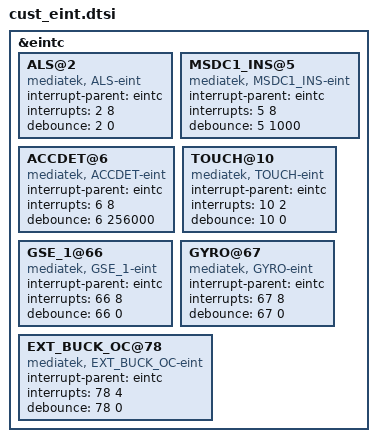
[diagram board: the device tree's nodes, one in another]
/*
 * Generated by MTK SP DrvGen Version 03.13.6 for MT6735M. Copyright MediaTek Inc. (C) 2013.
 * Fri Jan 06 15:19:48 2017
 * Do Not Modify the File.
 */

/*************************
 * EINT DTSI File
*************************/

&eintc {
	ALS@2 {
		compatible = "mediatek, ALS-eint";
		interrupt-parent = <&eintc>;
		interrupts = <2 8>;
		debounce = <2 0>;
	};

	MSDC1_INS@5 {
		compatible = "mediatek, MSDC1_INS-eint";
		interrupt-parent = <&eintc>;
		interrupts = <5 8>;
		debounce = <5 1000>;
	};

	ACCDET@6 {
		compatible = "mediatek, ACCDET-eint";
		interrupt-parent = <&eintc>;
		interrupts = <6 8>;
		debounce = <6 256000>;
	};

	TOUCH@10 {
		compatible = "mediatek, TOUCH-eint";
		interrupt-parent = <&eintc>;
		interrupts = <10 2>;
		debounce = <10 0>;
	};

	GSE_1@66 {
		compatible = "mediatek, GSE_1-eint";
		interrupt-parent = <&eintc>;
		interrupts = <66 8>;
		debounce = <66 0>;
	};

	GYRO@67 {
		compatible = "mediatek, GYRO-eint";
		interrupt-parent = <&eintc>;
		interrupts = <67 8>;
		debounce = <67 0>;
	};

	EXT_BUCK_OC@78 {
		compatible = "mediatek, EXT_BUCK_OC-eint";
		interrupt-parent = <&eintc>;
		interrupts = <78 4>;
		debounce = <78 0>;
	};

};
